# ATSAM4CMS16C_0 register map
Vendor: Atmel; Series: SAM4CM; File version: 0
CPU: CM4 r0p0, selectable endian, MPU, no FPU, 4 interrupt priority bits
Registers are 32-bit, read-write, reset 0x0 unless marked. A register's access mark holds for its fields unless they carry their own. Offsets are from the block's base; [hi:lo] are bit positions; {n}, {i} and the like mark numbered series.

## AES — Advanced Encryption Standard
Base 0x40000000; register names take the prefix AES_
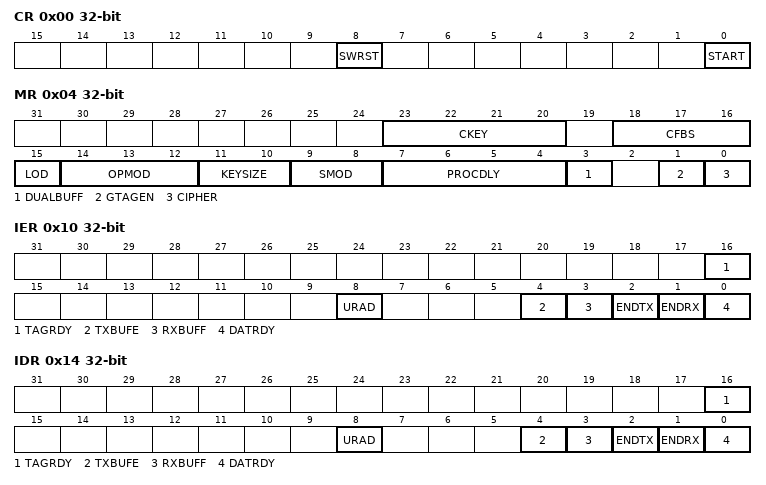
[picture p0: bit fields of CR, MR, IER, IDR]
0x00 CR wo reset not defined — Control Register
  [8] SWRST — Software Reset
  [0] START — Start Processing
0x04 MR — Mode Register
  [23:20] CKEY — Key
    14=PASSWD (This field must be written with 0xE the first time that AES_MR is programmed. For subsequent programming of the AES_MR, any value can be written, including that of 0xE.Always reads as 0.)
  [18:16] CFBS — Cipher Feedback Data Size
    0=SIZE_128BIT (128-bit); 1=SIZE_64BIT (64-bit); 2=SIZE_32BIT (32-bit); 3=SIZE_16BIT (16-bit); 4=SIZE_8BIT (8-bit)
  [15] LOD — Last Output Data Mode
  [14:12] OPMOD — Operation Mode
    0=ECB (ECB: Electronic Code Book mode); 1=CBC (CBC: Cipher Block Chaining mode); 2=OFB (OFB: Output Feedback mode); 3=CFB (CFB: Cipher Feedback mode); 4=CTR (CTR: Counter mode (16-bit internal counter)); 5=GCM (GCM: Galois/Counter mode)
  [11:10] KEYSIZE
    0=AES128 (AES Key Size is 128 bits); 1=AES192 (AES Key Size is 192 bits); 2=AES256 (AES Key Size is 256 bits)
  [9:8] SMOD — Start Mode
    0=MANUAL_START (Manual Mode); 1=AUTO_START (Auto Mode); 2=IDATAR0_START (AES_IDATAR0 access only Auto Mode)
  [7:4] PROCDLY — Processing Delay
  [3] DUALBUFF — Dual Input Buffer
    0=INACTIVE (AES_IDATARx cannot be written during processing of previous block.); 1=ACTIVE (AES_IDATARx can be written during processing of previous block when SMOD = 0x2. It speeds up the overall runtime of large files.)
  [1] GTAGEN — GCM Automatic Tag Generation Enable
  [0] CIPHER — Processing Mode
0x10 IER wo reset not defined — Interrupt Enable Register
  [16] TAGRDY — GCM Tag Ready Interrupt Enable
  [8] URAD — Unspecified Register Access Detection Interrupt Enable
  [4] TXBUFE — Transmit Buffer Empty Interrupt Enable
  [3] RXBUFF — Receive Buffer Full Interrupt Enable
  [2] ENDTX — End of Transmit Buffer Interrupt Enable
  [1] ENDRX — End of Receive Buffer Interrupt Enable
  [0] DATRDY — Data Ready Interrupt Enable
0x14 IDR wo reset not defined — Interrupt Disable Register
  [16] TAGRDY — GCM Tag Ready Interrupt Disable
  [8] URAD — Unspecified Register Access Detection Interrupt Disable
  [4] TXBUFE — Transmit Buffer Empty Interrupt Disable
  [3] RXBUFF — Receive Buffer Full Interrupt Disable
  [2] ENDTX — End of Transmit Buffer Interrupt Disable
  [1] ENDRX — End of Receive Buffer Interrupt Disable
  [0] DATRDY — Data Ready Interrupt Disable
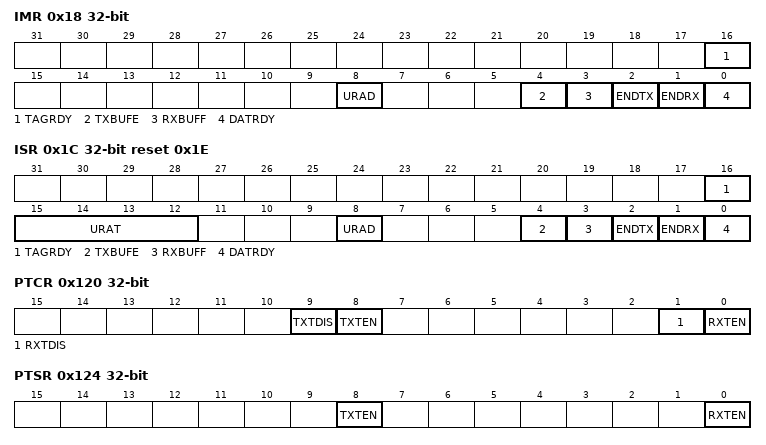
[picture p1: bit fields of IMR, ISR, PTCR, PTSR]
0x18 IMR ro — Interrupt Mask Register
  [16] TAGRDY — GCM Tag Ready Interrupt Mask
  [8] URAD — Unspecified Register Access Detection Interrupt Mask
  [4] TXBUFE — Transmit Buffer Empty Interrupt Mask
  [3] RXBUFF — Receive Buffer Full Interrupt Mask
  [2] ENDTX — End of Transmit Buffer Interrupt Mask
  [1] ENDRX — End of Receive Buffer Interrupt Mask
  [0] DATRDY — Data Ready Interrupt Mask
0x1C ISR ro reset 0x1E — Interrupt Status Register
  [16] TAGRDY — GCM Tag Ready
  [15:12] URAT — Unspecified Register Access
    0=IDR_WR_PROCESSING (Input Data Register written during the data processing when SMOD = 0x2 mode.); 1=ODR_RD_PROCESSING (Output Data Register read during the data processing.); 2=MR_WR_PROCESSING (Mode Register written during the data processing.); 3=ODR_RD_SUBKGEN (Output Data Register read during the sub-keys generation.); 4=MR_WR_SUBKGEN (Mode Register written during the sub-keys generation.); 5=WOR_RD_ACCESS (Write-only register read access.)
  [8] URAD — Unspecified Register Access Detection Status
  [4] TXBUFE — TX Buffer Empty
  [3] RXBUFF — RX Buffer Full
  [2] ENDTX — End of TX Buffer
  [1] ENDRX — End of RX Buffer
  [0] DATRDY — Data Ready
{0x20+4i} KEYWR[{i}] (i=0..7) wo reset not defined — Key Word Register
  [31:0] KEYW — Key Word
{0x40+4i} IDATAR[{i}] (i=0..3) wo reset not defined — Input Data Register
  [31:0] IDATA — Input Data Word
{0x50+4i} ODATAR[{i}] (i=0..3) ro reset not defined — Output Data Register
  [31:0] ODATA — Output Data
{0x60+4i} IVR[{i}] (i=0..3) wo reset not defined — Initialization Vector Register
  [31:0] IV — Initialization Vector
0x70 AADLENR reset not defined — Additional Authenticated Data Length Register
  [31:0] AADLEN — Additional Authenticated Data Length
0x74 CLENR reset not defined — Plaintext/Ciphertext Length Register
  [31:0] CLEN — Plaintext/Ciphertext Length
{0x78+4i} GHASHR[{i}] (i=0..3) reset not defined — GCM Intermediate Hash Word Register
  [31:0] GHASH — Intermediate GCM Hash Word x
{0x88+4i} TAGR[{i}] (i=0..3) ro reset not defined — GCM Authentication Tag Word Register
  [31:0] TAG — GCM Authentication Tag x
0x98 CTRR ro reset not defined — GCM Encryption Counter Value Register
  [31:0] CTR — GCM Encryption Counter
{0x9C+4i} GCMHR[{i}] (i=0..3) reset not defined — GCM H Word Register
  [31:0] H — GCM H Word x
0x100 RPR — Receive Pointer Register
  [31:0] RXPTR
0x104 RCR — Receive Counter Register
  [15:0] RXCTR
0x108 TPR — Transmit Pointer Register
  [31:0] TXPTR — Transmit Counter Register
0x10C TCR — Transmit Counter Register
  [15:0] TXCTR
0x110 RNPR — Receive Next Pointer Register
  [31:0] RXNPTR — Receive Next Pointer
0x114 RNCR — Receive Next Counter Register
  [15:0] RXNCTR — Receive Next Counter
0x118 TNPR — Transmit Next Pointer Register
  [31:0] TXNPTR — Transmit Next Pointer
0x11C TNCR — Transmit Next Counter Register
  [15:0] TXNCTR — Transmit Counter Next
0x120 PTCR wo — Transfer Control Register
  [9] TXTDIS — Transmitter Transfer Disable
  [8] TXTEN — Transmitter Transfer Enable
  [1] RXTDIS — Receiver Transfer Disable
  [0] RXTEN — Receiver Transfer Enable
0x124 PTSR ro — Transfer Status Register
  [8] TXTEN — Transmitter Transfer Enable
  [0] RXTEN — Receiver Transfer Enable

## Notices in the file
SAM Software Package License
Copyright (c) 2015, Atmel Corporation
All rights reserved.
Redistribution and use in source and binary forms, with or without
modification, are permitted provided that the following condition is met:
- Redistributions of source code must retain the above copyright notice,
this list of conditions and the disclaimer below.
Atmel's name may not be used to endorse or promote products derived from
this software without specific prior written permission.
DISCLAIMER:  THIS SOFTWARE IS PROVIDED BY ATMEL "AS IS" AND ANY EXPRESS OR
IMPLIED WARRANTIES, INCLUDING, BUT NOT LIMITED TO, THE IMPLIED WARRANTIES OF
MERCHANTABILITY, FITNESS FOR A PARTICULAR PURPOSE AND NON-INFRINGEMENT ARE
DISCLAIMED. IN NO EVENT SHALL ATMEL BE LIABLE FOR ANY DIRECT, INDIRECT,
INCIDENTAL, SPECIAL, EXEMPLARY, OR CONSEQUENTIAL DAMAGES (INCLUDING, BUT NOT
LIMITED TO, PROCUREMENT OF SUBSTITUTE GOODS OR SERVICES; LOSS OF USE, DATA,
OR PROFITS; OR BUSINESS INTERRUPTION) HOWEVER CAUSED AND ON ANY THEORY OF
LIABILITY, WHETHER IN CONTRACT, STRICT LIABILITY, OR TORT (INCLUDING
NEGLIGENCE OR OTHERWISE) ARISING IN ANY WAY OUT OF THE USE OF THIS SOFTWARE,
EVEN IF ADVISED OF THE POSSIBILITY OF SUCH DAMAGE.
